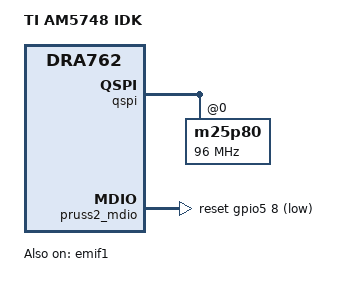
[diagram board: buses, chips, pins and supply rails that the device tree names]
// SPDX-License-Identifier: GPL-2.0
/*
 * Copyright (C) 2017 Texas Instruments Incorporated - http://www.ti.com/
 */


/dts-v1/;

#include "dra74x-p.dtsi"
#include "dra7-mmc-iodelay.dtsi"
#include "dra76x-mmc-iodelay.dtsi"
#include "am572x-idk-common.dtsi"

/ {
	model = "TI AM5748 IDK";
	compatible = "ti,am5728-idk", "ti,dra762", "ti,dra7";
};

&qspi {
	spi-max-frequency = <96000000>;
	m25p80@0 {
		spi-max-frequency = <96000000>;
	};
};

&mmc1 {
	pinctrl-names = "default", "hs";
	pinctrl-0 = <&mmc1_pins_default_no_clk_pu>;
	pinctrl-1 = <&mmc1_pins_hs>;
};

&mmc2 {
	pinctrl-names = "default", "hs", "ddr_3_3v";
	pinctrl-0 = <&mmc2_pins_default>;
	pinctrl-1 = <&mmc2_pins_default>;
	pinctrl-2 = <&mmc2_pins_default>;
};

&emif1 {
	status = "okay";
};

&pruss2_mdio {
	reset-gpios = <&gpio5 8 GPIO_ACTIVE_LOW>,
		      <&gpio5 9 GPIO_ACTIVE_LOW>;
	reset-delay-us = <2>;   /* PHY datasheet states 1uS min */
};
